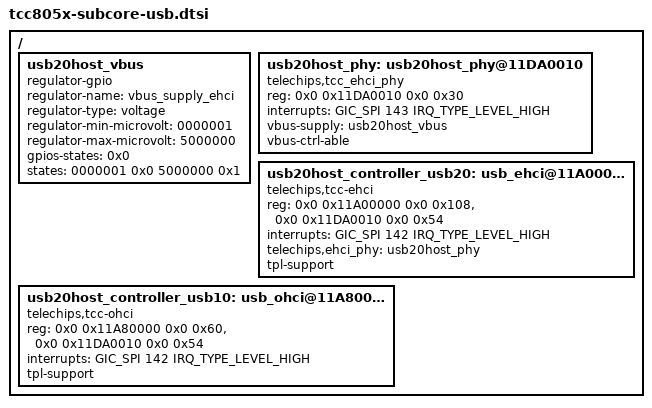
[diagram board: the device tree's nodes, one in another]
// SPDX-License-Identifier: (GPL-2.0-or-later OR MIT)
/*
 * Copyright (C) Telechips Inc.
 */

#include <dt-bindings/interrupt-controller/arm-gic.h>

/ {
	usb20host_vbus: usb20host_vbus {
		compatible = "regulator-gpio";
		regulator-name = "vbus_supply_ehci";
		regulator-type = "voltage";
		regulator-min-microvolt = <0000001>;
		regulator-max-microvolt = <5000000>;
		gpios-states = <0x0>;
		states = <0000001 0x0 5000000 0x1>;
		status = "okay";
	};

	usb20host_phy: usb20host_phy@11DA0010 {
		compatible = "telechips,tcc_ehci_phy";
		reg = <0x0 0x11DA0010 0x0 0x30>;
		interrupts = <GIC_SPI 143 IRQ_TYPE_LEVEL_HIGH>;
		vbus-supply = <&usb20host_vbus>;
		vbus-ctrl-able;
		status = "okay";
	};

	/* USB 2.0 controller for high speed : EHCI */
	usb20host_controller_usb20: usb_ehci@11A00000 {
		compatible = "telechips,tcc-ehci";
		reg = <0x0 0x11A00000 0x0 0x108>,
			<0x0 0x11DA0010 0x0 0x54>;
		interrupts = <GIC_SPI 142 IRQ_TYPE_LEVEL_HIGH>;
		telechips,ehci_phy = <&usb20host_phy>;
		tpl-support;
		status = "okay";
	};

	/* USB 1.0 controller for full speed and low speed : OHCI */
	usb20host_controller_usb10: usb_ohci@11A80000 {
		compatible = "telechips,tcc-ohci";
		reg = <0x0 0x11A80000 0x0 0x60>,
			<0x0 0x11DA0010 0x0 0x54>;
		interrupts = <GIC_SPI 142 IRQ_TYPE_LEVEL_HIGH>;
		tpl-support;
		status = "okay";
	};
};
